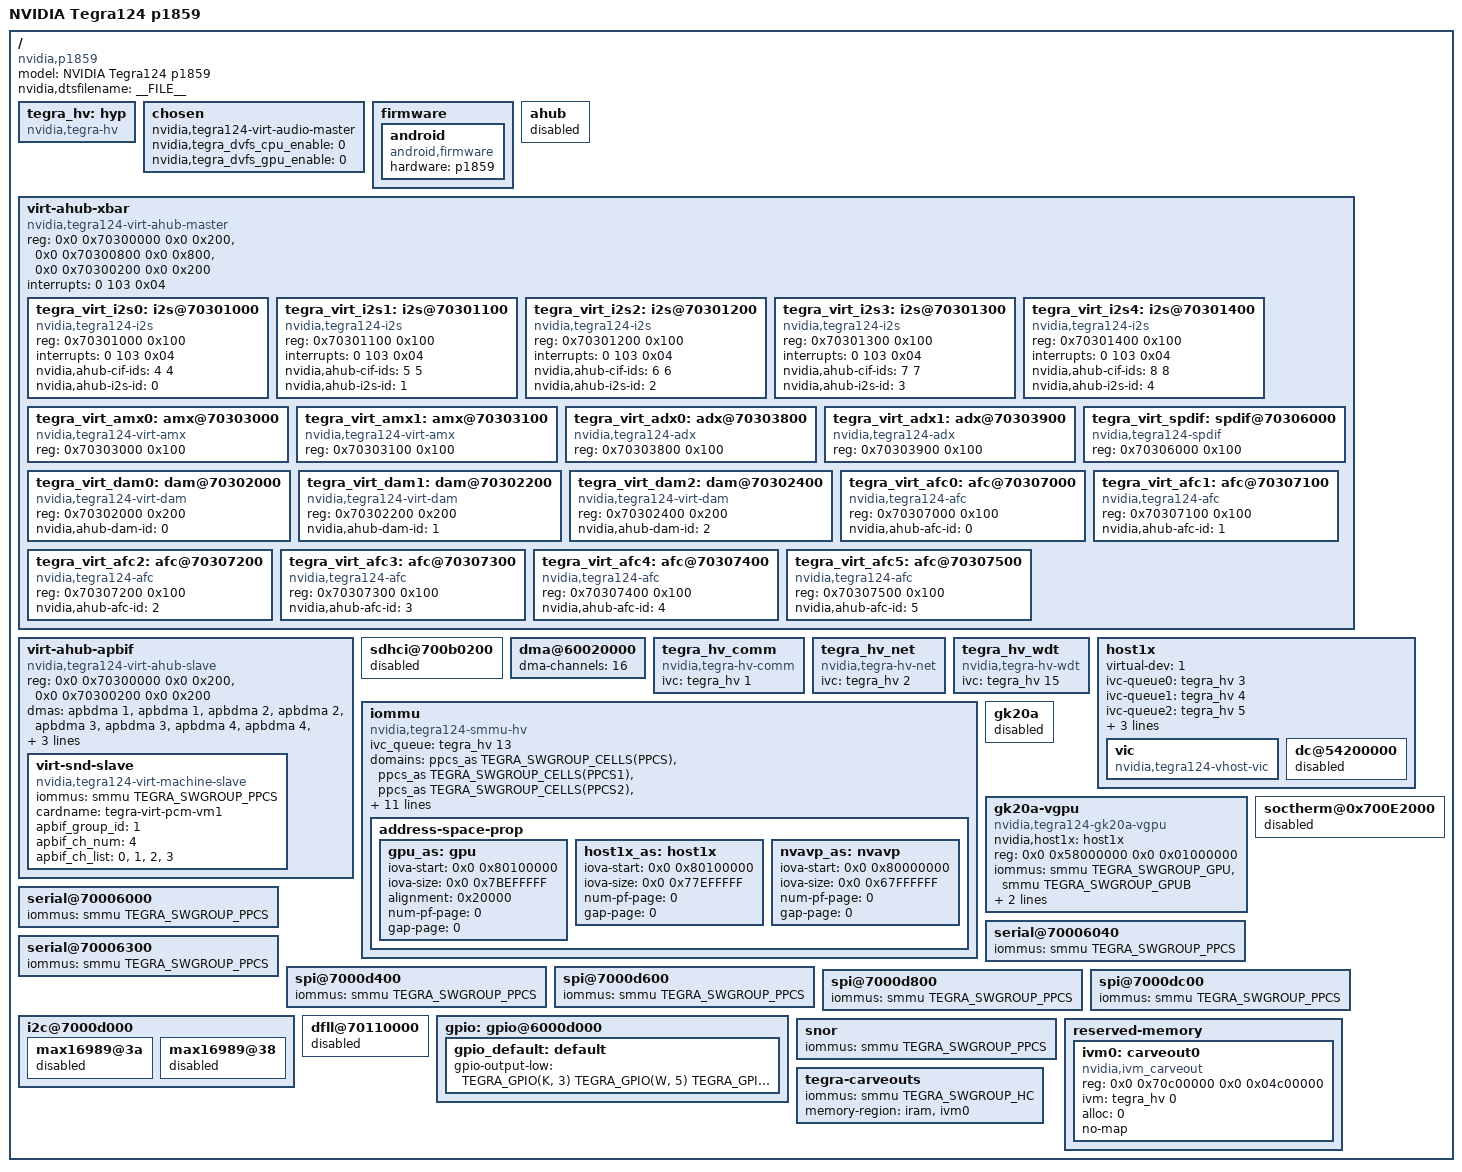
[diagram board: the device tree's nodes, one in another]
/*
 * arch/arm/boot/dts/tegra124-p1859-vm_1.dts
 *
 * Copyright (c) 2013-2015, NVIDIA CORPORATION.  All rights reserved.
 *
 * This program is free software; you can redistribute it and/or modify
 * it under the terms of the GNU General Public License as published by
 * the Free Software Foundation; version 2 of the License.
 *
 * This program is distributed in the hope that it will be useful, but WITHOUT
 * ANY WARRANTY; without even the implied warranty of MERCHANTABILITY or
 * FITNESS FOR A PARTICULAR PURPOSE.  See the GNU General Public License for
 * more details.
 *
 * You should have received a copy of the GNU General Public License along
 * with this program; if not, write to the Free Software Foundation, Inc.,
 * 51 Franklin Street, Fifth Floor, Boston, MA  02110-1301, USA.
 *
 */
 /dts-v1/;

/ {
	/* smmu and ivc drivers are called very early in the kernel init
	 * call sequence (core_initcall). smmu driver as such is a consumer
	 * of ivc and depends on it.
	 * Keeping the ivc node at the very top in the device tree ensures
	 * that probe for ivc is called before the smmu driver probe.
	 * Without this virtualized smmu driver probe will fail.
	 */
	tegra_hv: hyp {
		compatible = "nvidia,tegra-hv";
		status = "okay";
	};
};

#include "tegra124-p1859.dtsi"

/ {
	model = "NVIDIA Tegra124 p1859";
	compatible = "nvidia,p1859", "nvidia,tegra124";
	nvidia,dtsfilename = __FILE__;

	chosen {
		nvidia,tegra124-virt-audio-master;
	};

	firmware {
		android {
			compatible = "android,firmware";
			hardware = "p1859";
		};
	};

	ahub {
		status = "disabled";
	};

	virt-ahub-xbar {
		compatible = "nvidia,tegra124-virt-ahub-master";
		reg = <0x0 0x70300000 0x0 0x200>,
			<0x0 0x70300800 0x0 0x800>,
			<0x0 0x70300200 0x0 0x200>;
		interrupts = <0 103 0x04>;
		status = "okay";

		#address-cells = <1>;
		#size-cells = <1>;

		ranges = <0x70300000 0x0 0x70300000 0x00010000>;

		tegra_virt_i2s0: i2s@70301000 {
			compatible = "nvidia,tegra124-i2s";
			reg = <0x70301000 0x100>;
			interrupts = <0 103 0x04>;
			nvidia,ahub-cif-ids = <4 4>;
			nvidia,ahub-i2s-id = <0>;
			status = "okay";
		};

		tegra_virt_i2s1: i2s@70301100 {
			compatible = "nvidia,tegra124-i2s";
			reg = <0x70301100 0x100>;
			interrupts = <0 103 0x04>;
			nvidia,ahub-cif-ids = <5 5>;
			nvidia,ahub-i2s-id = <1>;
			status = "okay";
		};

		tegra_virt_i2s2: i2s@70301200 {
			compatible = "nvidia,tegra124-i2s";
			reg = <0x70301200 0x100>;
			interrupts = <0 103 0x04>;
			nvidia,ahub-cif-ids = <6 6>;
			nvidia,ahub-i2s-id = <2>;
			status = "okay";
		};

		tegra_virt_i2s3: i2s@70301300 {
			compatible = "nvidia,tegra124-i2s";
			reg = <0x70301300 0x100>;
			interrupts = <0 103 0x04>;
			nvidia,ahub-cif-ids = <7 7>;
			nvidia,ahub-i2s-id = <3>;
			status = "okay";
		};

		tegra_virt_i2s4: i2s@70301400 {
			compatible = "nvidia,tegra124-i2s";
			reg = <0x70301400 0x100>;
			interrupts = <0 103 0x04>;
			nvidia,ahub-cif-ids = <8 8>;
			nvidia,ahub-i2s-id = <4>;
			status = "okay";
		};

		tegra_virt_amx0: amx@70303000 {
			compatible = "nvidia,tegra124-virt-amx";
			reg = <0x70303000 0x100>;
			status = "okay";
		};

		tegra_virt_amx1: amx@70303100 {
			compatible = "nvidia,tegra124-virt-amx";
			reg = <0x70303100 0x100>;
			status = "okay";
		};

		tegra_virt_adx0: adx@70303800 {
			compatible = "nvidia,tegra124-adx";
			reg = <0x70303800 0x100>;
			status = "okay";
		};

		tegra_virt_adx1: adx@70303900 {
			compatible = "nvidia,tegra124-adx";
			reg = <0x70303900 0x100>;
			status = "okay";
		};

		tegra_virt_spdif: spdif@70306000 {
			compatible = "nvidia,tegra124-spdif";
			reg = <0x70306000 0x100>;
			status = "okay";
		};

		tegra_virt_dam0: dam@70302000 {
			compatible = "nvidia,tegra124-virt-dam";
			reg = <0x70302000 0x200>;
			nvidia,ahub-dam-id = <0>;
			status = "okay";
		};

		tegra_virt_dam1: dam@70302200 {
			compatible = "nvidia,tegra124-virt-dam";
			reg = <0x70302200 0x200>;
			nvidia,ahub-dam-id = <1>;
			status = "okay";
		};

		tegra_virt_dam2: dam@70302400 {
			compatible = "nvidia,tegra124-virt-dam";
			reg = <0x70302400 0x200>;
			nvidia,ahub-dam-id = <2>;
			status = "okay";
		};

		tegra_virt_afc0: afc@70307000 {
			compatible = "nvidia,tegra124-afc";
			reg = <0x70307000 0x100>;
			nvidia,ahub-afc-id = <0>;
			status = "okay";
		};

		tegra_virt_afc1: afc@70307100 {
			compatible = "nvidia,tegra124-afc";
			reg = <0x70307100 0x100>;
			nvidia,ahub-afc-id = <1>;
			status = "okay";
		};

		tegra_virt_afc2: afc@70307200 {
			compatible = "nvidia,tegra124-afc";
			reg = <0x70307200 0x100>;
			nvidia,ahub-afc-id = <2>;
			status = "okay";
		};

		tegra_virt_afc3: afc@70307300 {
			compatible = "nvidia,tegra124-afc";
			reg = <0x70307300 0x100>;
			nvidia,ahub-afc-id = <3>;
			status = "okay";
		};

		tegra_virt_afc4: afc@70307400 {
			compatible = "nvidia,tegra124-afc";
			reg = <0x70307400 0x100>;
			nvidia,ahub-afc-id = <4>;
			status = "okay";
		};

		tegra_virt_afc5: afc@70307500 {
			compatible = "nvidia,tegra124-afc";
			reg = <0x70307500 0x100>;
			nvidia,ahub-afc-id = <5>;
			status = "okay";
		};

	};

	virt-ahub-apbif {
			compatible = "nvidia,tegra124-virt-ahub-slave";
			reg = <0x0 0x70300000 0x0 0x200>,
					<0x0 0x70300200 0x0 0x200>;
			dmas =	<&apbdma 1>, <&apbdma 1>, <&apbdma 2>, <&apbdma 2>,
					 <&apbdma 3>, <&apbdma 3>, <&apbdma 4>, <&apbdma 4>,
					 <&apbdma 6>, <&apbdma 6>, <&apbdma 7>, <&apbdma 7>,
					 <&apbdma 12>, <&apbdma 12>, <&apbdma 13>, <&apbdma 13>,
					 <&apbdma 14>, <&apbdma 14>, <&apbdma 29>, <&apbdma 29>;
			dma-names =	"rx0", "tx0", "rx1", "tx1", "rx2", "tx2",
					"rx3", "tx3", "rx4", "tx4", "rx5", "tx5",
					"rx6", "tx6", "rx7", "tx7", "rx8", "tx8",
					"rx9", "tx9";
			status = "okay";

			virt-snd-slave {
					compatible = "nvidia,tegra124-virt-machine-slave";
					iommus = < &smmu TEGRA_SWGROUP_PPCS >;
					status = "okay";
					cardname = "tegra-virt-pcm-vm1";
			/*
			** The default nvaudio_conf_virt_audio.xml file for the VMs expect the apbif channels
			** to be (0, 1, 2, 3) if the apbif_group_id is set to 1 and
			** (4, 5, 6, 7, 8, 9) if the apbif_group_id is set to 2. If random apbif
			** channels has to be assigned, corresponding change has to be made in
			** the nvaudio_conf_virt_audio.xml file also.
			*/
					apbif_group_id = <1>;
					apbif_ch_num = <4>;
					apbif_ch_list = <0>, <1>, <2>, <3>;
			};
	};

	sdhci@700b0200 {
		status = "disabled";
	};

	dma@60020000 {
		dma-channels = <16>;
		status = "okay";
	};

	/* the virtual serial device node */
	tegra_hv_comm {
		compatible = "nvidia,tegra-hv-comm";
		status = "okay";
		/* ivc channel to use definition (second one in tegra_hv) */
		ivc = <&tegra_hv 1>;
	};

	tegra_hv_net {
		compatible = "nvidia,tegra-hv-net";
		status = "okay";
		ivc = <&tegra_hv 2>;
	};

	tegra_hv_wdt {
		compatible = "nvidia,tegra-hv-wdt";
		status = "okay";
		ivc = <&tegra_hv 15>;
	};

	iommu {
		compatible = "nvidia,tegra124-smmu-hv";
		ivc_queue = <&tegra_hv 13>;

		domains = <
			&ppcs_as TEGRA_SWGROUP_CELLS(PPCS)
			&ppcs_as TEGRA_SWGROUP_CELLS(PPCS1)
			&ppcs_as TEGRA_SWGROUP_CELLS(PPCS2)
			&gpu_as TEGRA_SWGROUP_CELLS(GPUB)
			&dc_as TEGRA_SWGROUP_CELLS2(DC, DC12)
			&dc_as TEGRA_SWGROUP_CELLS(DCB)
			&common_as TEGRA_SWGROUP_CELLS(AFI)
			&common_as TEGRA_SWGROUP_CELLS(SDMMC1A)
			&common_as TEGRA_SWGROUP_CELLS(SDMMC2A)
			&common_as TEGRA_SWGROUP_CELLS(SDMMC3A)
			&common_as TEGRA_SWGROUP_CELLS(SDMMC4A)
			&host1x_as TEGRA_SWGROUP_CELLS9(EPP, HC, HDA, VI, ISP, ISP2B, VIC, MSENC, TSEC)
			&nvavp_as TEGRA_SWGROUP_CELLS3(AVPC, A9AVP, VDE)
			&common_as 0xFFFFFFFF 0xFFFFFFFF>;

		address-space-prop {
			gpu_as: gpu {
				iova-start = <0x0 0x80100000>;
				iova-size = <0x0 0x7BEFFFFF>;
				alignment = <0x20000>;
				num-pf-page = <0>;
				gap-page = <0>;
			};

			host1x_as: host1x {
				iova-start = <0x0 0x80100000>;
				iova-size = <0x0 0x77EFFFFF>;
				num-pf-page = <0>;
				gap-page = <0>;
			};

			nvavp_as: nvavp {
				iova-start = <0x0 0x80000000>;
				iova-size = <0x0 0x67FFFFFF>;
				num-pf-page = <0>;
				gap-page = <0>;
			};
		};
	};

	host1x {
		virtual-dev = <1>;

		ivc-queue0 = <&tegra_hv 3>;
		ivc-queue1 = <&tegra_hv 4>;
		ivc-queue2 = <&tegra_hv 5>;

		iommus = <&smmu TEGRA_SWGROUP_EPP>,
			<&smmu TEGRA_SWGROUP_HC>,
			<&smmu TEGRA_SWGROUP_HDA>;

		vic {
			compatible = "nvidia,tegra124-vhost-vic";
		};

		/delete-node/ dpaux;
		/delete-node/ sor;

		/* tegradc.0 */
		dc@54200000 {
			status = "disabled";
		};

	};

	gk20a {
		status = "disabled";
	};

	gk20a-vgpu {
		compatible = "nvidia,tegra124-gk20a-vgpu";
		nvidia,host1x = <&host1x>;
		reg = <0x0 0x58000000 0x0 0x01000000>;
		iommus = <&smmu TEGRA_SWGROUP_GPU &smmu TEGRA_SWGROUP_GPUB>;

		ivc-queue3 = <&tegra_hv 6>;
		ivc-queue4 = <&tegra_hv 7>;
	};

	chosen {
		nvidia,tegra_dvfs_cpu_enable = <0>;
		nvidia,tegra_dvfs_gpu_enable = <0>;
	};

	soctherm@0x700E2000 {
		status = "disabled";
	};

	serial@70006000 {
		iommus = <&smmu TEGRA_SWGROUP_PPCS>;
		status = "okay";
	};

	serial@70006040 {
		iommus = <&smmu TEGRA_SWGROUP_PPCS>;
		status = "okay";
	};

	serial@70006300 {
		iommus = <&smmu TEGRA_SWGROUP_PPCS>;
		status = "okay";
	};

	spi@7000d400 {
		iommus = <&smmu TEGRA_SWGROUP_PPCS>;
		status = "okay";
	};

	spi@7000d600 {
		iommus = <&smmu TEGRA_SWGROUP_PPCS>;
		status = "okay";
	};

	spi@7000d800 {
		iommus = <&smmu TEGRA_SWGROUP_PPCS>;
		status = "okay";
	};

	spi@7000dc00 {
		iommus = <&smmu TEGRA_SWGROUP_PPCS>;
		status = "okay";
	};

	i2c@7000d000 {
		status = "okay";

		max16989@3a {
			status = "disabled";
		};

		max16989@38 {
			status = "disabled";
		};
	};

	dfll@70110000 {
		status = "disabled";
	};

	gpio: gpio@6000d000 {
		gpio_default: default {
		gpio-output-low = <TEGRA_GPIO(K, 3)
				TEGRA_GPIO(W, 5)
				TEGRA_GPIO(R, 3)
				TEGRA_GPIO(R, 5)
				TEGRA_GPIO(R, 6)>;
		};
	};

	snor {
		iommus = <&smmu TEGRA_SWGROUP_PPCS>;
		status = "okay";
	};

	reserved-memory {
		ivm0: carveout0 {
			compatible = "nvidia,ivm_carveout";
			reg = <0x0 0x70c00000 0x0 0x04c00000>;
			ivm = <&tegra_hv 0>;
			alloc = <0>;
			no-map;
		};
	};

	tegra-carveouts {
		iommus = <&smmu TEGRA_SWGROUP_HC>;
		status = "okay";
		memory-region = <&iram &ivm0>;
	};
};
